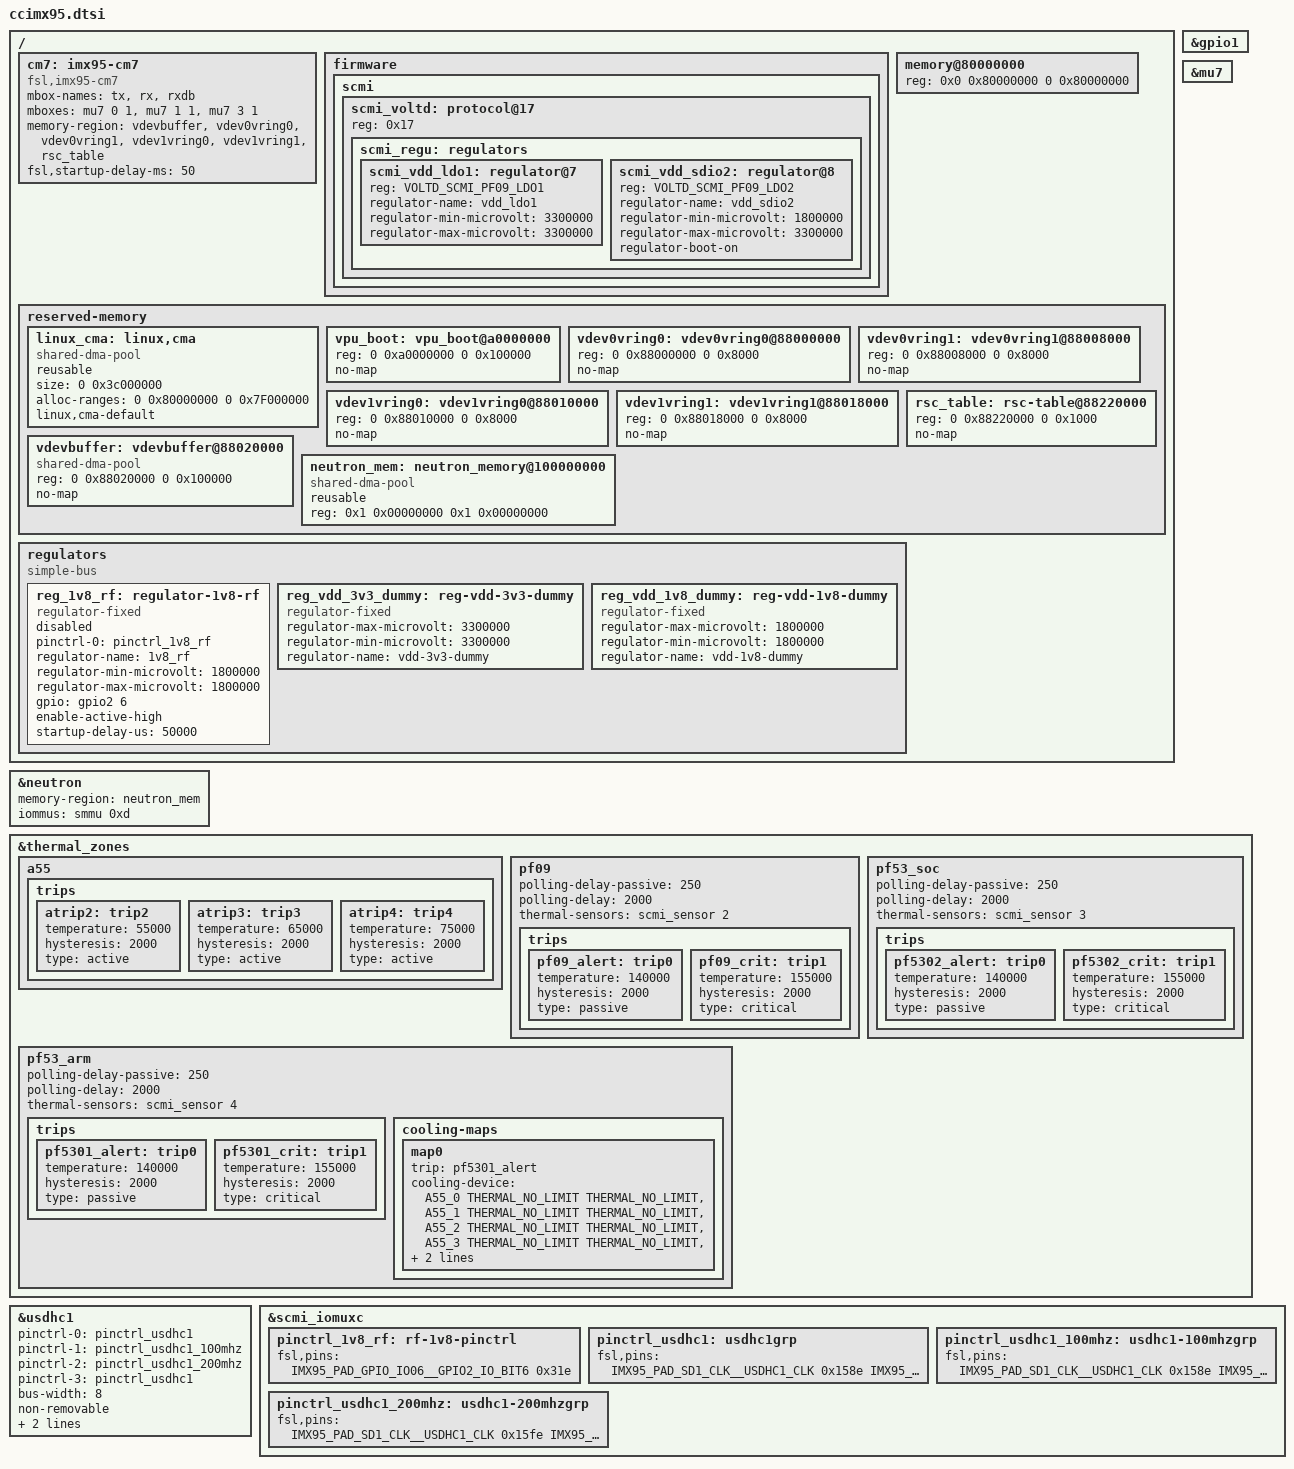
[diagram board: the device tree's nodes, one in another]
// SPDX-License-Identifier: (GPL-2.0+ OR MIT)
/*
 * Copyright 2025 Digi International Inc.
 */

#include <dt-bindings/regulator/nxp,pf09-regulator.h>

/ {
	cm7: imx95-cm7 {
		compatible = "fsl,imx95-cm7";
		mbox-names = "tx", "rx", "rxdb";
		mboxes = <&mu7 0 1
			  &mu7 1 1
			  &mu7 3 1>;
		memory-region = <&vdevbuffer>, <&vdev0vring0>, <&vdev0vring1>,
				<&vdev1vring0>, <&vdev1vring1>, <&rsc_table>;
		fsl,startup-delay-ms = <50>;
		status = "okay";
	};

	firmware {
		scmi {
			scmi_voltd: protocol@17 {
				reg = <0x17>;

				scmi_regu: regulators {
					#address-cells = <1>;
					#size-cells = <0>;

					scmi_vdd_ldo1: regulator@7 {
						reg = <VOLTD_SCMI_PF09_LDO1>;
						regulator-name = "vdd_ldo1";
						regulator-min-microvolt = <3300000>;
						regulator-max-microvolt = <3300000>;
					};

					scmi_vdd_sdio2: regulator@8 {
						reg = <VOLTD_SCMI_PF09_LDO2>;
						regulator-name = "vdd_sdio2";
						regulator-min-microvolt = <1800000>;
						regulator-max-microvolt = <3300000>;
						regulator-boot-on;
					};
				};
			};
		};
	};

	memory@80000000 {
		device_type = "memory";
		reg = <0x0 0x80000000 0 0x80000000>;
	};

	reserved-memory {
		#address-cells = <2>;
		#size-cells = <2>;
		ranges;

		linux_cma: linux,cma {
			compatible = "shared-dma-pool";
			reusable;
			size = <0 0x3c000000>;
			alloc-ranges = <0 0x80000000 0 0x7F000000>;
			linux,cma-default;
		};

		vpu_boot: vpu_boot@a0000000 {
			reg = <0 0xa0000000 0 0x100000>;
			no-map;
		};

		vdev0vring0: vdev0vring0@88000000 {
			reg = <0 0x88000000 0 0x8000>;
			no-map;
		};

		vdev0vring1: vdev0vring1@88008000 {
			reg = <0 0x88008000 0 0x8000>;
			no-map;
		};

		vdev1vring0: vdev1vring0@88010000 {
			reg = <0 0x88010000 0 0x8000>;
			no-map;
		};

		vdev1vring1: vdev1vring1@88018000 {
			reg = <0 0x88018000 0 0x8000>;
			no-map;
		};

		rsc_table: rsc-table@88220000 {
			reg = <0 0x88220000 0 0x1000>;
			no-map;
		};

		vdevbuffer: vdevbuffer@88020000 {
			compatible = "shared-dma-pool";
			reg = <0 0x88020000 0 0x100000>;
			no-map;
		};

		neutron_mem: neutron_memory@100000000 {
			compatible = "shared-dma-pool";
			reusable;
			reg = <0x1 0x00000000 0x1 0x00000000>;
		};
	};

	regulators {
		compatible = "simple-bus";
		#address-cells = <1>;
		#size-cells = <0>;

		/* Wi-Fi 1v8 */
		reg_1v8_rf: regulator-1v8-rf {
			compatible = "regulator-fixed";
			pinctrl-names = "default";
			pinctrl-0 = <&pinctrl_1v8_rf>;
			regulator-name = "1v8_rf";
			regulator-min-microvolt = <1800000>;
			regulator-max-microvolt = <1800000>;
			gpio = <&gpio2 6 GPIO_ACTIVE_HIGH>; /* RF_EN */
			enable-active-high;
			startup-delay-us = <50000>;
			status = "disabled";
		};

		/*
		 * Dummy regulators to satisfy drivers supplies.
		 * These should really be the PMIC's regulators (via SCMI), but the
		 * current System Manager (SM) firmware is not able to:
		 * - not switch them off during a reboot sequence
		 * - switch them off during a poweroff sequence
		 */
		reg_vdd_3v3_dummy: reg-vdd-3v3-dummy {
			compatible = "regulator-fixed";
			regulator-max-microvolt = <3300000>;
			regulator-min-microvolt = <3300000>;
			regulator-name = "vdd-3v3-dummy";
		};

		reg_vdd_1v8_dummy: reg-vdd-1v8-dummy {
			compatible = "regulator-fixed";
			regulator-max-microvolt = <1800000>;
			regulator-min-microvolt = <1800000>;
			regulator-name = "vdd-1v8-dummy";
		};
	};
};

&neutron {
	memory-region = <&neutron_mem>;
	iommus = <&smmu 0xd>;
};

/* Enable GPIO1 to be used in Linux (not reserved by SM) */
&gpio1 {
	status = "okay";
};

/* Messaging Units for inter-processors communication */
&mu7 {
	status = "okay";
};

&thermal_zones {
	a55 {
		trips {
			atrip2: trip2 {
				temperature = <55000>;
				hysteresis = <2000>;
				type = "active";
			};

			atrip3: trip3 {
				temperature = <65000>;
				hysteresis = <2000>;
				type = "active";
			};

			atrip4: trip4 {
				temperature = <75000>;
				hysteresis = <2000>;
				type = "active";
			};
		};
	};

	pf09 {
		polling-delay-passive = <250>;
		polling-delay = <2000>;
		thermal-sensors = <&scmi_sensor 2>;
		trips {
			pf09_alert: trip0 {
				temperature = <140000>;
				hysteresis = <2000>;
				type = "passive";
			};

			pf09_crit: trip1 {
				temperature = <155000>;
				hysteresis = <2000>;
				type = "critical";
			};
		};
	};

	pf53_arm {
		polling-delay-passive = <250>;
		polling-delay = <2000>;
		thermal-sensors = <&scmi_sensor 4>;
		trips {
			pf5301_alert: trip0 {
				temperature = <140000>;
				hysteresis = <2000>;
				type = "passive";
			};

			pf5301_crit: trip1 {
				temperature = <155000>;
				hysteresis = <2000>;
				type = "critical";
			};
		};

		cooling-maps {
			map0 {
				trip = <&pf5301_alert>;
				cooling-device =
					<&A55_0 THERMAL_NO_LIMIT THERMAL_NO_LIMIT>,
					<&A55_1 THERMAL_NO_LIMIT THERMAL_NO_LIMIT>,
					<&A55_2 THERMAL_NO_LIMIT THERMAL_NO_LIMIT>,
					<&A55_3 THERMAL_NO_LIMIT THERMAL_NO_LIMIT>,
					<&A55_4 THERMAL_NO_LIMIT THERMAL_NO_LIMIT>,
					<&A55_5 THERMAL_NO_LIMIT THERMAL_NO_LIMIT>;
			};
		};
	};

	pf53_soc {
		polling-delay-passive = <250>;
		polling-delay = <2000>;
		thermal-sensors = <&scmi_sensor 3>;
		trips {
			pf5302_alert: trip0 {
				temperature = <140000>;
				hysteresis = <2000>;
				type = "passive";
			};

			pf5302_crit: trip1 {
				temperature = <155000>;
				hysteresis = <2000>;
				type = "critical";
			};
		};
	};
};

/* eMMC */
&usdhc1 {
	pinctrl-names = "default", "state_100mhz", "state_200mhz", "sleep";
	pinctrl-0 = <&pinctrl_usdhc1>;
	pinctrl-1 = <&pinctrl_usdhc1_100mhz>;
	pinctrl-2 = <&pinctrl_usdhc1_200mhz>;
	pinctrl-3 = <&pinctrl_usdhc1>;
	bus-width = <8>;
	non-removable;
	no-sdio;
	no-sd;
	status = "okay";
};

&scmi_iomuxc {
	/* Wi-Fi 1v8 RF_EN */
	pinctrl_1v8_rf: rf-1v8-pinctrl {
		fsl,pins = <
			/* RF_EN */
			IMX95_PAD_GPIO_IO06__GPIO2_IO_BIT6	0x31e
		>;
	};

	pinctrl_usdhc1: usdhc1grp {
		fsl,pins = <
			IMX95_PAD_SD1_CLK__USDHC1_CLK		0x158e
			IMX95_PAD_SD1_CMD__USDHC1_CMD		0x138e
			IMX95_PAD_SD1_DATA0__USDHC1_DATA0	0x138e
			IMX95_PAD_SD1_DATA1__USDHC1_DATA1	0x138e
			IMX95_PAD_SD1_DATA2__USDHC1_DATA2	0x138e
			IMX95_PAD_SD1_DATA3__USDHC1_DATA3	0x138e
			IMX95_PAD_SD1_DATA4__USDHC1_DATA4	0x138e
			IMX95_PAD_SD1_DATA5__USDHC1_DATA5	0x138e
			IMX95_PAD_SD1_DATA6__USDHC1_DATA6	0x138e
			IMX95_PAD_SD1_DATA7__USDHC1_DATA7	0x138e
			IMX95_PAD_SD1_STROBE__USDHC1_STROBE	0x158e
		>;
	};

	pinctrl_usdhc1_100mhz: usdhc1-100mhzgrp {
		fsl,pins = <
			IMX95_PAD_SD1_CLK__USDHC1_CLK		0x158e
			IMX95_PAD_SD1_CMD__USDHC1_CMD		0x138e
			IMX95_PAD_SD1_DATA0__USDHC1_DATA0	0x138e
			IMX95_PAD_SD1_DATA1__USDHC1_DATA1	0x138e
			IMX95_PAD_SD1_DATA2__USDHC1_DATA2	0x138e
			IMX95_PAD_SD1_DATA3__USDHC1_DATA3	0x138e
			IMX95_PAD_SD1_DATA4__USDHC1_DATA4	0x138e
			IMX95_PAD_SD1_DATA5__USDHC1_DATA5	0x138e
			IMX95_PAD_SD1_DATA6__USDHC1_DATA6	0x138e
			IMX95_PAD_SD1_DATA7__USDHC1_DATA7	0x138e
			IMX95_PAD_SD1_STROBE__USDHC1_STROBE	0x158e
		>;
	};

	pinctrl_usdhc1_200mhz: usdhc1-200mhzgrp {
		fsl,pins = <
			IMX95_PAD_SD1_CLK__USDHC1_CLK		0x15fe
			IMX95_PAD_SD1_CMD__USDHC1_CMD		0x13fe
			IMX95_PAD_SD1_DATA0__USDHC1_DATA0	0x13fe
			IMX95_PAD_SD1_DATA1__USDHC1_DATA1	0x13fe
			IMX95_PAD_SD1_DATA2__USDHC1_DATA2	0x13fe
			IMX95_PAD_SD1_DATA3__USDHC1_DATA3	0x13fe
			IMX95_PAD_SD1_DATA4__USDHC1_DATA4	0x13fe
			IMX95_PAD_SD1_DATA5__USDHC1_DATA5	0x13fe
			IMX95_PAD_SD1_DATA6__USDHC1_DATA6	0x13fe
			IMX95_PAD_SD1_DATA7__USDHC1_DATA7	0x13fe
			IMX95_PAD_SD1_STROBE__USDHC1_STROBE	0x15fe
		>;
	};
};
